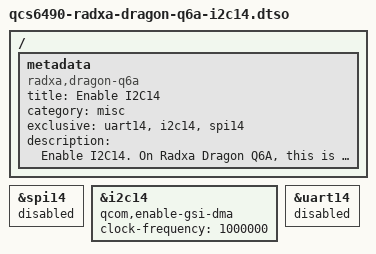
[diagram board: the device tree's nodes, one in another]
// SPDX-License-Identifier: BSD-3-Clause
/*
 * Copyright (c) 2025 Radxa Computer (Shenzhen) Co., Ltd.
 */

/dts-v1/;
/plugin/;

/ {
	metadata {
		title = "Enable I2C14";
		compatible = "radxa,dragon-q6a";
		category = "misc";
		exclusive = "uart14","i2c14","spi14";
		description = "Enable I2C14. 
On Radxa Dragon Q6A, this is pin 22(scl), 33(sda).";
	};
};

&spi14 {
	status = "disabled";
};

&i2c14 {
	qcom,enable-gsi-dma;
	status = "okay";

	clock-frequency = <1000000>;
};

&uart14 {
	status = "disabled";
};
